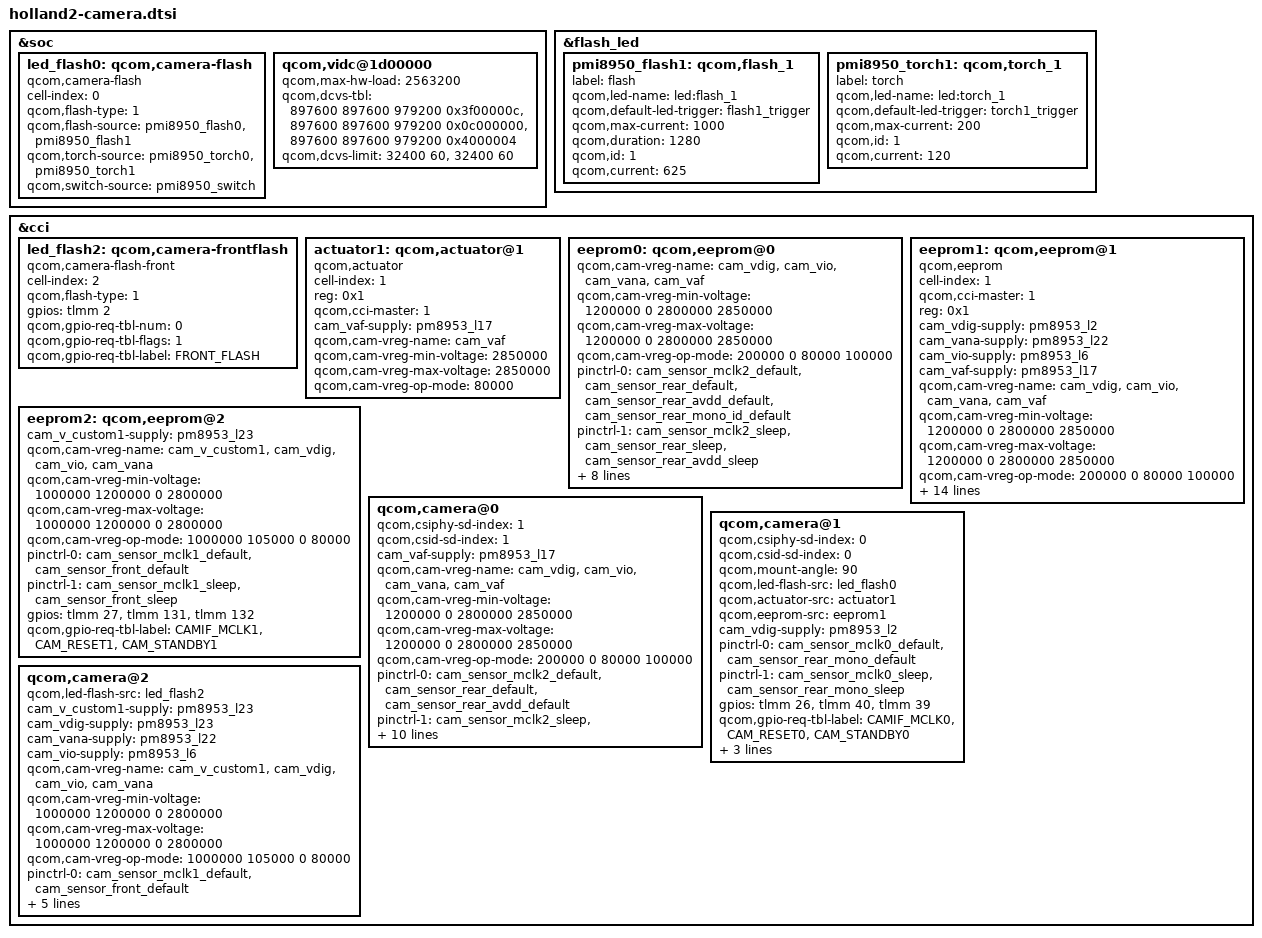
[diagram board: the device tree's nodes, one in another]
/* Copyright (c) 2020, The Linux Foundation. All rights reserved.
*  Copyright (c) 2020, Jebaitedneko.
*
* This program is free software; you can redistribute it and/or modify
* it under the terms of the GNU General Public License version 2 and
* only version 2 as published by the Free Software Foundation.
*
* This program is distributed in the hope that it will be useful,
* but WITHOUT ANY WARRANTY; without even the implied warranty of
* MERCHANTABILITY or FITNESS FOR A PARTICULAR PURPOSE.  See the
* GNU General Public License for more details.
*/

&soc {

	led_flash0: qcom,camera-flash {

		cell-index = <0>;
		compatible = "qcom,camera-flash";
		qcom,flash-type = <1>;
		qcom,flash-source = <&pmi8950_flash0 &pmi8950_flash1>;
		qcom,torch-source = <&pmi8950_torch0 &pmi8950_torch1>;
		qcom,switch-source = <&pmi8950_switch>;
	};

	qcom,vidc@1d00000 {
		qcom,max-hw-load = <2563200>; /* Full 4k @ 60 + 1080p @ 60 */
		qcom,dcvs-tbl =
			/* Dec UHD@30 H.264, HEVC, VP8, VP9 - NOM to NOM+*/
			<897600 897600 979200 0x3f00000c>,

			/* Enc UHD@30 H.264/HEVC Turbo to Nom+ */
			<897600 897600 979200 0x0c000000>,

			/* Enc True4K@24 H.264/HEVC Nom to Nom+ */
			<897600 897600 979200 0x4000004>;
		qcom,dcvs-limit =
			<32400 60>, /* Encoder UHD */
			<32400 60>; /* Decoder UHD */
	};
};

&flash_led {

	pmi8950_flash1: qcom,flash_1 {

		label = "flash";
		qcom,led-name = "led:flash_1";
		qcom,default-led-trigger =
				"flash1_trigger";
		qcom,max-current = <1000>;
		qcom,duration = <1280>;
		qcom,id = <1>;
		qcom,current = <625>;
	};

	pmi8950_torch1: qcom,torch_1 {

		label = "torch";
		qcom,led-name = "led:torch_1";
		qcom,default-led-trigger =
				"torch1_trigger";
		qcom,max-current = <200>;
		qcom,id = <1>;
		qcom,current = <120>;
	};
};

&cci {

	led_flash2: qcom,camera-frontflash {

		cell-index = <2>;
		compatible = "qcom,camera-flash-front";
		qcom,flash-type = <1>;
		gpios = <&tlmm 2 0>;
		qcom,gpio-req-tbl-num = <0>;
		qcom,gpio-req-tbl-flags = <1>;
		qcom,gpio-req-tbl-label = "FRONT_FLASH";
	};

	actuator1: qcom,actuator@1 {

		cell-index = <1>;
		reg = <0x1>;
		compatible = "qcom,actuator";
		qcom,cci-master = <1>;
		cam_vaf-supply = <&pm8953_l17>;
		qcom,cam-vreg-name = "cam_vaf";
		qcom,cam-vreg-min-voltage = <2850000>;
		qcom,cam-vreg-max-voltage = <2850000>;
		qcom,cam-vreg-op-mode = <80000>;
	};

	eeprom0: qcom,eeprom@0 {

		qcom,cam-vreg-name = "cam_vdig", "cam_vio", "cam_vana",
							"cam_vaf";
		qcom,cam-vreg-min-voltage = <1200000 0 2800000 2850000>;
		qcom,cam-vreg-max-voltage = <1200000 0 2800000 2850000>;
		qcom,cam-vreg-op-mode = <200000 0 80000 100000>;
		pinctrl-0 = <&cam_sensor_mclk2_default
				&cam_sensor_rear_default
				&cam_sensor_rear_avdd_default
				&cam_sensor_rear_mono_id_default>;
		pinctrl-1 = <&cam_sensor_mclk2_sleep
				&cam_sensor_rear_sleep
				&cam_sensor_rear_avdd_sleep>;
		gpios = <&tlmm 28 0>,
			<&tlmm 129 0>,
			<&tlmm 130 0>,
			<&tlmm 46 0>;
		qcom,gpio-vana = <3>;
		qcom,gpio-req-tbl-num = <0 1 2 3>;
		qcom,gpio-req-tbl-flags = <1 0 0 0>;
		qcom,gpio-req-tbl-label = "CAMIF_MCLK2",
			"CAM_RESET2",
			"CAM_STANDBY2",
			"CAM_VANA2";
		clocks = <&clock_gcc clk_mclk2_clk_src>,
				<&clock_gcc clk_gcc_camss_mclk2_clk>;
	};

	eeprom1: qcom,eeprom@1 {

		status = "okay";

		cell-index = <1>;
		compatible = "qcom,eeprom";
		qcom,cci-master = <1>;
		reg = <0x1>;
		cam_vdig-supply = <&pm8953_l2>;
		cam_vana-supply = <&pm8953_l22>;
		cam_vio-supply = <&pm8953_l6>;
		cam_vaf-supply = <&pm8953_l17>;
		qcom,cam-vreg-name = "cam_vdig", "cam_vio", "cam_vana",
							"cam_vaf";
		qcom,cam-vreg-min-voltage = <1200000 0 2800000 2850000>;
		qcom,cam-vreg-max-voltage = <1200000 0 2800000 2850000>;
		qcom,cam-vreg-op-mode = <200000 0 80000 100000>;
		pinctrl-names = "cam_default", "cam_suspend";
		pinctrl-0 = <&cam_sensor_mclk0_default
				&cam_sensor_rear_mono_default>;
		pinctrl-1 = <&cam_sensor_mclk0_sleep
				&cam_sensor_rear_mono_sleep>;
		gpios = <&tlmm 26 0>,
			<&tlmm 40 0>,
			<&tlmm 39 0>;
		qcom,gpio-reset = <1>;
		qcom,gpio-standby = <2>;
		qcom,gpio-req-tbl-num = <0 1 2>;
		qcom,gpio-req-tbl-flags = <1 0 0>;
		qcom,gpio-req-tbl-label = "CAMIF_MCLK0",
			"CAM_RESET0",
			"CAM_STANDBY0";
		clocks = <&clock_gcc clk_mclk0_clk_src>,
				<&clock_gcc clk_gcc_camss_mclk0_clk>;
		clock-names = "cam_src_clk", "cam_clk";
		qcom,clock-rates = <19200000 0>;
	};

	eeprom2: qcom,eeprom@2 {

		cam_v_custom1-supply = <&pm8953_l23>;
		qcom,cam-vreg-name = "cam_v_custom1","cam_vdig", "cam_vio", "cam_vana";
		qcom,cam-vreg-min-voltage = <1000000 1200000 0 2800000>;
		qcom,cam-vreg-max-voltage = <1000000 1200000 0 2800000>;
		qcom,cam-vreg-op-mode = <1000000 105000 0 80000>;
		pinctrl-0 = <&cam_sensor_mclk1_default 
				&cam_sensor_front_default>;
		pinctrl-1 = <&cam_sensor_mclk1_sleep
				&cam_sensor_front_sleep>;
		gpios = <&tlmm 27 0>,
			<&tlmm 131 0>,
			<&tlmm 132 0>;
		qcom,gpio-req-tbl-label = "CAMIF_MCLK1",
					  "CAM_RESET1",
					  "CAM_STANDBY1";
	};

	qcom,camera@0 {

		qcom,csiphy-sd-index = <1>;
		qcom,csid-sd-index = <1>;
		cam_vaf-supply = <&pm8953_l17>;
		qcom,cam-vreg-name = "cam_vdig", "cam_vio", "cam_vana",
							"cam_vaf";
		qcom,cam-vreg-min-voltage = <1200000 0 2800000 2850000>;
		qcom,cam-vreg-max-voltage = <1200000 0 2800000 2850000>;
		qcom,cam-vreg-op-mode = <200000 0 80000 100000>;
		pinctrl-0 = <&cam_sensor_mclk2_default
				&cam_sensor_rear_default
				&cam_sensor_rear_avdd_default>;
		pinctrl-1 = <&cam_sensor_mclk2_sleep
				&cam_sensor_rear_sleep
				&cam_sensor_rear_avdd_sleep>;
		gpios = <&tlmm 28 0>,
			<&tlmm 129 0>,
			<&tlmm 130 0>,
			<&tlmm 46 0>;
		qcom,gpio-vana = <3>;
		qcom,gpio-req-tbl-num = <0 1 2 3>;
		qcom,gpio-req-tbl-flags = <1 0 0 0>;
		qcom,gpio-req-tbl-label = "CAMIF_MCLK2",
			"CAM_RESET2",
			"CAM_STANDBY2",
			"CAM_VANA2";
		clocks = <&clock_gcc clk_mclk2_clk_src>,
			<&clock_gcc clk_gcc_camss_mclk2_clk>;

		/delete-property/ cam_vana-supply;

	};

	qcom,camera@1 {

		status = "okay";

		qcom,csiphy-sd-index = <0>;
		qcom,csid-sd-index = <0>;
		qcom,mount-angle = <90>;
		qcom,led-flash-src = <&led_flash0>;
		qcom,actuator-src = <&actuator1>;
		qcom,eeprom-src = <&eeprom1>;
		cam_vdig-supply = <&pm8953_l2>;
		pinctrl-0 = <&cam_sensor_mclk0_default
				&cam_sensor_rear_mono_default>;
		pinctrl-1 = <&cam_sensor_mclk0_sleep
				&cam_sensor_rear_mono_sleep>;
		gpios = <&tlmm 26 0>,
			<&tlmm 40 0>,
			<&tlmm 39 0>;
		qcom,gpio-req-tbl-label = "CAMIF_MCLK0",
			"CAM_RESET0",
			"CAM_STANDBY0";
		qcom,cci-master = <1>;
		clocks = <&clock_gcc clk_mclk0_clk_src>,
				<&clock_gcc clk_gcc_camss_mclk0_clk>;
	};

	qcom,camera@2 {

		qcom,led-flash-src = <&led_flash2>;
		cam_v_custom1-supply = <&pm8953_l23>;
		cam_vdig-supply = <&pm8953_l23>;
		cam_vana-supply = <&pm8953_l22>;
		cam_vio-supply = <&pm8953_l6>;
		qcom,cam-vreg-name = "cam_v_custom1","cam_vdig", "cam_vio", "cam_vana";
		qcom,cam-vreg-min-voltage = <1000000 1200000 0 2800000>;
		qcom,cam-vreg-max-voltage = <1000000 1200000 0 2800000>;
		qcom,cam-vreg-op-mode = <1000000 105000 0 80000>;
		pinctrl-0 = <&cam_sensor_mclk1_default
				&cam_sensor_front_default>;
		pinctrl-1 = <&cam_sensor_mclk1_sleep
				&cam_sensor_front_sleep>;
		gpios = <&tlmm 27 0>,
			<&tlmm 131 0>,
			<&tlmm 132 0>;
		qcom,gpio-req-tbl-label = "CAMIF_MCLK1",
					  "CAM_RESET1",
					  "CAM_STANDBY1";
	};
};
